# nrf52840 register map
Vendor: Nordic Semiconductor; Series: nrf52; File version: 1
CPU: CM4 r0p1, little endian, MPU, FPU, 3 interrupt priority bits
Registers are 32-bit, read-write, reset 0x0 unless marked. A register's access mark holds for its fields unless they carry their own. Offsets are from the block's base; [hi:lo] are bit positions; {n}, {i} and the like mark numbered series; 'fields as' and 'values as' point back to an identical list.

## TIMER0 — Timer/Counter 0
Base 0x40008000
Same registers: TIMER1 0x40009000, TIMER2 0x4000A000, TIMER3 0x4001A000, TIMER4 0x4001B000
0x00 TASKS_START wo — Start Timer
  [0] TASKS_START
0x04 TASKS_STOP wo — Stop Timer
  [0] TASKS_STOP
0x08 TASKS_COUNT wo — Increment Timer (Counter mode only)
  [0] TASKS_COUNT
0x0C TASKS_CLEAR wo — Clear time
  [0] TASKS_CLEAR
0x10 TASKS_SHUTDOWN wo — Deprecated register - Shut down timer
  [0] TASKS_SHUTDOWN
{0x40+4i} TASKS_CAPTURE[{i}] (i=0..5) wo — Description collection[n]: Capture Timer value to CC[n] register
  [0] TASKS_CAPTURE
{0x140+4i} EVENTS_COMPARE[{i}] (i=0..5) — Description collection[n]: Compare event on CC[n] match
  [0] EVENTS_COMPARE
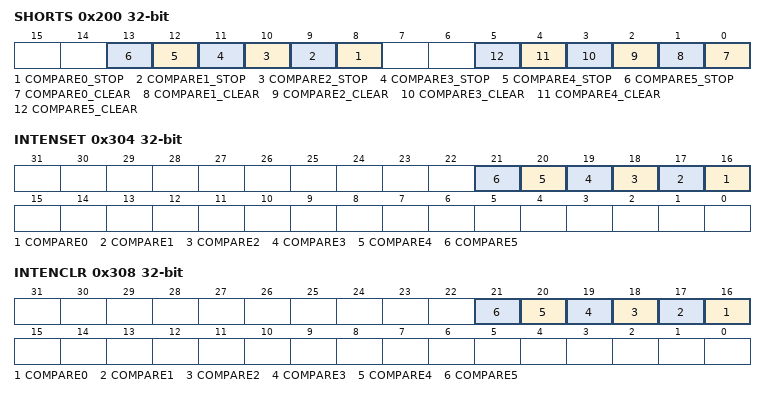
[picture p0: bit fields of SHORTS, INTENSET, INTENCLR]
0x200 SHORTS — Shortcut register
  [all] fields
    0=Disabled (Disable shortcut); 1=Enabled (Enable shortcut)
  [n+8] COMPARE{n}_STOP (n=0..5) — Shortcut between COMPARE[{n}] event and STOP task
  [n] COMPARE{n}_CLEAR (n=0..5) — Shortcut between COMPARE[{n}] event and CLEAR task
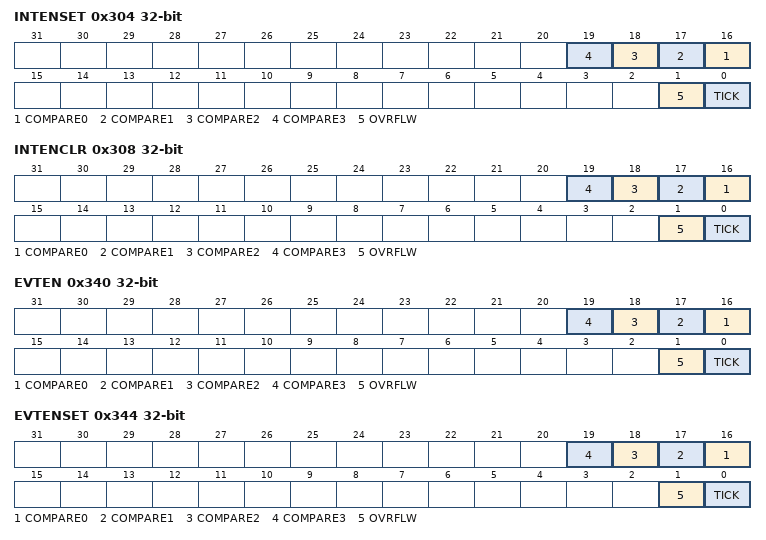
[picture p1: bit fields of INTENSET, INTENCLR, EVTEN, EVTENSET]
0x304 INTENSET — Enable interrupt
  [all] fields
    on read: 0=Disabled (Read: Disabled); 1=Enabled (Read: Enabled) | on write: 1=Set (Enable)
  [n+16] COMPARE{n} (n=0..5) — Write '1' to enable interrupt for COMPARE[{n}] event
0x308 INTENCLR — Disable interrupt
  [all] fields
    on read: 0=Disabled (Read: Disabled); 1=Enabled (Read: Enabled) | on write: 1=Clear (Disable)
  [n+16] COMPARE{n} (n=0..5) — Write '1' to disable interrupt for COMPARE[{n}] event
0x504 MODE — Timer mode selection
  [1:0] MODE — Timer mode
    0=Timer (Select Timer mode); 1=Counter (Deprecated enumerator - Select Counter mode); 2=LowPowerCounter (Select Low Power Counter mode)
0x508 BITMODE — Configure the number of bits used by the TIMER
  [1:0] BITMODE — Timer bit width
    0=16 bit timer bit width; 1=08Bit (8 bit timer bit width); 2=24 bit timer bit width; 3=32 bit timer bit width
0x510 PRESCALER reset 0x4 — Timer prescaler register
  [3:0] PRESCALER — Prescaler value
{0x540+4i} CC[{i}] (i=0..5) — Description collection[n]: Capture/Compare register n
  [31:0] CC — Capture/Compare value

## RTC0 — Real time counter 0
Base 0x4000B000
Same registers: RTC1 0x40011000, RTC2 0x40024000
0x00 TASKS_START wo — Start RTC COUNTER
  [0] TASKS_START
0x04 TASKS_STOP wo — Stop RTC COUNTER
  [0] TASKS_STOP
0x08 TASKS_CLEAR wo — Clear RTC COUNTER
  [0] TASKS_CLEAR
0x0C TASKS_TRIGOVRFLW wo — Set COUNTER to 0xFFFFF0
  [0] TASKS_TRIGOVRFLW
0x100 EVENTS_TICK — Event on COUNTER increment
  [0] EVENTS_TICK
0x104 EVENTS_OVRFLW — Event on COUNTER overflow
  [0] EVENTS_OVRFLW
{0x140+4i} EVENTS_COMPARE[{i}] (i=0..3) — Description collection[n]: Compare event on CC[n] match
  [0] EVENTS_COMPARE
0x304 INTENSET — Enable interrupt
  [all] fields
    on read: 0=Disabled (Read: Disabled); 1=Enabled (Read: Enabled) | on write: 1=Set (Enable)
  [n+16] COMPARE{n} (n=0..3) — Write '1' to enable interrupt for COMPARE[{n}] event
  [1] OVRFLW — Write '1' to enable interrupt for OVRFLW event
  [0] TICK — Write '1' to enable interrupt for TICK event
0x308 INTENCLR — Disable interrupt
  [all] fields
    on read: 0=Disabled (Read: Disabled); 1=Enabled (Read: Enabled) | on write: 1=Clear (Disable)
  [n+16] COMPARE{n} (n=0..3) — Write '1' to disable interrupt for COMPARE[{n}] event
  [1] OVRFLW — Write '1' to disable interrupt for OVRFLW event
  [0] TICK — Write '1' to disable interrupt for TICK event
0x340 EVTEN — Enable or disable event routing
  [all] fields
    0=Disabled; 1=Enabled
  [n+16] COMPARE{n} (n=0..3) — Enable or disable event routing for COMPARE[{n}] event
  [1] OVRFLW — Enable or disable event routing for OVRFLW event
  [0] TICK — Enable or disable event routing for TICK event
0x344 EVTENSET — Enable event routing
  [all] fields
    values as the fields of INTENSET
  [n+16] COMPARE{n} (n=0..3) — Write '1' to enable event routing for COMPARE[{n}] event
  [1] OVRFLW — Write '1' to enable event routing for OVRFLW event
  [0] TICK — Write '1' to enable event routing for TICK event
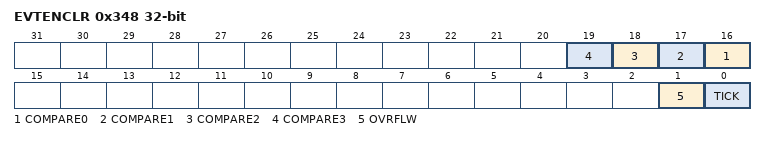
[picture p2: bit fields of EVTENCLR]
0x348 EVTENCLR — Disable event routing
  [all] fields
    values as the fields of INTENCLR
  [n+16] COMPARE{n} (n=0..3) — Write '1' to disable event routing for COMPARE[{n}] event
  [1] OVRFLW — Write '1' to disable event routing for OVRFLW event
  [0] TICK — Write '1' to disable event routing for TICK event
0x504 COUNTER ro — Current COUNTER value
  [23:0] COUNTER — Counter value
0x508 PRESCALER — 12 bit prescaler for COUNTER frequency (32768/(PRESCALER+1)).Must be written when RTC is stopped
  [11:0] PRESCALER — Prescaler value
{0x540+4i} CC[{i}] (i=0..3) — Description collection[n]: Compare register n
  [23:0] COMPARE — Compare value
